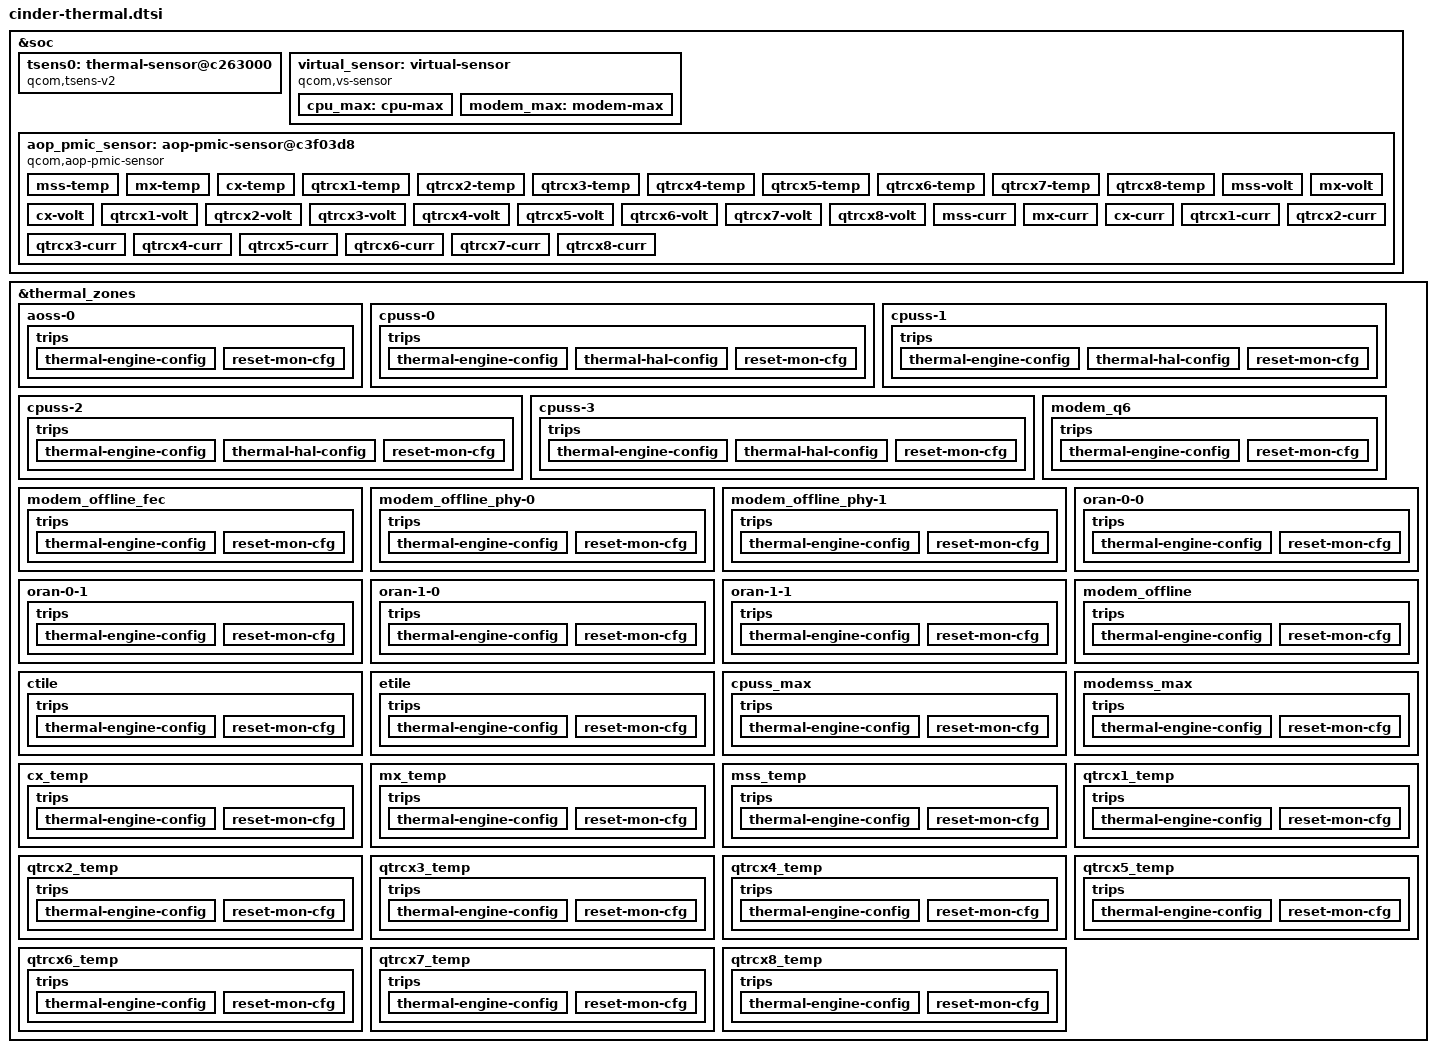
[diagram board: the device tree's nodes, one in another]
#include <dt-bindings/thermal/thermal_qti.h>

&soc {
	tsens0: thermal-sensor@c263000 {
		compatible = "qcom,tsens-v2";
		reg = <0x0c263000 0x1ff>, /* TM */
			<0x0c222000 0x1ff>; /* SROT */
		#qcom,sensors = <16>;
		interrupts = <GIC_SPI 499 IRQ_TYPE_LEVEL_HIGH>,
			     <GIC_SPI 501 IRQ_TYPE_LEVEL_HIGH>;
		interrupt-names = "uplow","critical";
		#thermal-sensor-cells = <1>;
	};

	virtual_sensor: virtual-sensor {
		compatible = "qcom,vs-sensor";
		#thermal-sensor-cells = <1>;

		cpu_max: cpu-max {
			sensor-names = "cpuss-0",
					"cpuss-1",
					"cpuss-2",
					"cpuss-3";
			qcom,logic = <1>;
		};

		modem_max: modem-max {
			sensor-names = "modem_q6",
					"modem_offline_fec",
					"modem_offline_phy-0",
					"modem_offline_phy-1",
					"modem_offline";
			qcom,logic = <1>;
		};
	};

    aop_pmic_sensor: aop-pmic-sensor@c3f03d8 {
        compatible = "qcom,aop-pmic-sensor";
		reg = <0x0c3e0200 0x140>;
		mboxes = <&qmp_aop 0>;
		#thermal-sensor-cells = <1>;

		mss-temp {
			qcom,pmic-id = <1>;
			qcom,type = <0>;
		};

		mx-temp {
			qcom,pmic-id = <2>;
			qcom,type = <0>;
		};

		cx-temp {
			qcom,pmic-id = <3>;
			qcom,type = <0>;
		};

		qtrcx1-temp {
			qcom,pmic-id = <13>;
			qcom,type = <0>;
		};

		qtrcx2-temp {
			qcom,pmic-id = <14>;
			qcom,type = <0>;
		};

		qtrcx3-temp {
			qcom,pmic-id = <15>;
			qcom,type = <0>;
		};

		qtrcx4-temp {
			qcom,pmic-id = <16>;
			qcom,type = <0>;
		};

		qtrcx5-temp {
			qcom,pmic-id = <17>;
			qcom,type = <0>;
		};

		qtrcx6-temp {
			qcom,pmic-id = <18>;
			qcom,type = <0>;
		};

		qtrcx7-temp {
			qcom,pmic-id = <19>;
			qcom,type = <0>;
		};

		qtrcx8-temp {
			qcom,pmic-id = <20>;
			qcom,type = <0>;
		};

		mss-volt {
			qcom,pmic-id = <1>;
			qcom,type = <1>;
		};

		mx-volt {
			qcom,pmic-id = <2>;
			qcom,type = <1>;
		};

		cx-volt {
			qcom,pmic-id = <3>;
			qcom,type = <1>;
		};

		qtrcx1-volt {
			qcom,pmic-id = <13>;
			qcom,type = <1>;
		};

		qtrcx2-volt {
			qcom,pmic-id = <14>;
			qcom,type = <1>;
		};

		qtrcx3-volt {
			qcom,pmic-id = <15>;
			qcom,type = <1>;
		};

		qtrcx4-volt {
			qcom,pmic-id = <16>;
			qcom,type = <1>;
		};

		qtrcx5-volt {
			qcom,pmic-id = <17>;
			qcom,type = <1>;
		};

		qtrcx6-volt {
			qcom,pmic-id = <18>;
			qcom,type = <1>;
		};

		qtrcx7-volt {
			qcom,pmic-id = <19>;
			qcom,type = <1>;
		};

		qtrcx8-volt {
			qcom,pmic-id = <20>;
			qcom,type = <1>;
		};

		mss-curr {
			qcom,pmic-id = <1>;
			qcom,type = <2>;
		};

		mx-curr {
			qcom,pmic-id = <2>;
			qcom,type = <2>;
		};

		cx-curr {
			qcom,pmic-id = <3>;
			qcom,type = <2>;
		};

		qtrcx1-curr {
			qcom,pmic-id = <13>;
			qcom,type = <2>;
		};

		qtrcx2-curr {
			qcom,pmic-id = <14>;
			qcom,type = <2>;
		};

		qtrcx3-curr {
			qcom,pmic-id = <15>;
			qcom,type = <2>;
		};

		qtrcx4-curr {
			qcom,pmic-id = <16>;
			qcom,type = <2>;
		};

		qtrcx5-curr {
			qcom,pmic-id = <17>;
			qcom,type = <2>;
		};

		qtrcx6-curr {
			qcom,pmic-id = <18>;
			qcom,type = <2>;
		};

		qtrcx7-curr {
			qcom,pmic-id = <19>;
			qcom,type = <2>;
		};

		qtrcx8-curr {
			qcom,pmic-id = <20>;
			qcom,type = <2>;
		};
    };
};

#include "cinder-thermal-modem.dtsi"

&thermal_zones {
	aoss-0 {
		polling-delay-passive = <0>;
		polling-delay = <0>;
		thermal-sensors = <&tsens0 0>;
		trips {
			thermal-engine-config {
				temperature = <125000>;
				hysteresis = <1000>;
				type = "passive";
			};

			reset-mon-cfg {
				temperature = <115000>;
				hysteresis = <5000>;
				type = "passive";
			};
		};
	};

	cpuss-0 {
		polling-delay-passive = <0>;
		polling-delay = <0>;
		thermal-sensors = <&tsens0 1>;
		trips {
			thermal-engine-config {
				temperature = <125000>;
				hysteresis = <1000>;
				type = "passive";
			};

			thermal-hal-config {
				temperature = <125000>;
				hysteresis = <1000>;
				type = "passive";
			};

			reset-mon-cfg {
				temperature = <115000>;
				hysteresis = <5000>;
				type = "passive";
			};
		};
	};

	cpuss-1 {
		polling-delay-passive = <0>;
		polling-delay = <0>;
		thermal-sensors = <&tsens0 2>;
		trips {
			thermal-engine-config {
				temperature = <125000>;
				hysteresis = <1000>;
				type = "passive";
			};

			thermal-hal-config {
				temperature = <125000>;
				hysteresis = <1000>;
				type = "passive";
			};

			reset-mon-cfg {
				temperature = <115000>;
				hysteresis = <5000>;
				type = "passive";
			};
		};
	};

	cpuss-2 {
		polling-delay-passive = <0>;
		polling-delay = <0>;
		thermal-sensors = <&tsens0 3>;
		trips {
			thermal-engine-config {
				temperature = <125000>;
				hysteresis = <1000>;
				type = "passive";
			};

			thermal-hal-config {
				temperature = <125000>;
				hysteresis = <1000>;
				type = "passive";
			};

			reset-mon-cfg {
				temperature = <115000>;
				hysteresis = <5000>;
				type = "passive";
			};
		};
	};

	cpuss-3 {
		polling-delay-passive = <0>;
		polling-delay = <0>;
		thermal-sensors = <&tsens0 4>;
		trips {
			thermal-engine-config {
				temperature = <125000>;
				hysteresis = <1000>;
				type = "passive";
			};

			thermal-hal-config {
				temperature = <125000>;
				hysteresis = <1000>;
				type = "passive";
			};

			reset-mon-cfg {
				temperature = <115000>;
				hysteresis = <5000>;
				type = "passive";
			};
		};
	};

	modem_q6 {
		polling-delay-passive = <0>;
		polling-delay = <0>;
		thermal-sensors = <&tsens0 5>;
		trips {
			thermal-engine-config {
				temperature = <125000>;
				hysteresis = <1000>;
				type = "passive";
			};

			reset-mon-cfg {
				temperature = <115000>;
				hysteresis = <5000>;
				type = "passive";
			};
		};
	};

	modem_offline_fec {
		polling-delay-passive = <0>;
		polling-delay = <0>;
		thermal-sensors = <&tsens0 6>;
		trips {
			thermal-engine-config {
				temperature = <125000>;
				hysteresis = <1000>;
				type = "passive";
			};

			reset-mon-cfg {
				temperature = <115000>;
				hysteresis = <5000>;
				type = "passive";
			};
		};
	};

	modem_offline_phy-0 {
		polling-delay-passive = <0>;
		polling-delay = <0>;
		thermal-sensors = <&tsens0 7>;
		trips {
			thermal-engine-config {
				temperature = <125000>;
				hysteresis = <1000>;
				type = "passive";
			};

			reset-mon-cfg {
				temperature = <115000>;
				hysteresis = <5000>;
				type = "passive";
			};
		};
	};

	modem_offline_phy-1 {
		polling-delay-passive = <0>;
		polling-delay = <0>;
		thermal-sensors = <&tsens0 8>;
		trips {
			thermal-engine-config {
				temperature = <125000>;
				hysteresis = <1000>;
				type = "passive";
			};

			reset-mon-cfg {
				temperature = <115000>;
				hysteresis = <5000>;
				type = "passive";
			};
		};
	};

	oran-0-0 {
		polling-delay-passive = <0>;
		polling-delay = <0>;
		thermal-sensors = <&tsens0 9>;
		trips {
			thermal-engine-config {
				temperature = <125000>;
				hysteresis = <1000>;
				type = "passive";
			};

			reset-mon-cfg {
				temperature = <115000>;
				hysteresis = <5000>;
				type = "passive";
			};
		};
	};

	oran-0-1 {
		polling-delay-passive = <0>;
		polling-delay = <0>;
		thermal-sensors = <&tsens0 10>;
		trips {
			thermal-engine-config {
				temperature = <125000>;
				hysteresis = <1000>;
				type = "passive";
			};

			reset-mon-cfg {
				temperature = <115000>;
				hysteresis = <5000>;
				type = "passive";
			};
		};
	};

	oran-1-0 {
		polling-delay-passive = <0>;
		polling-delay = <0>;
		thermal-sensors = <&tsens0 11>;
		trips {
			thermal-engine-config {
				temperature = <125000>;
				hysteresis = <1000>;
				type = "passive";
			};

			reset-mon-cfg {
				temperature = <115000>;
				hysteresis = <5000>;
				type = "passive";
			};
		};
	};

	oran-1-1 {
		polling-delay-passive = <0>;
		polling-delay = <0>;
		thermal-sensors = <&tsens0 12>;
		trips {
			thermal-engine-config {
				temperature = <125000>;
				hysteresis = <1000>;
				type = "passive";
			};

			reset-mon-cfg {
				temperature = <115000>;
				hysteresis = <5000>;
				type = "passive";
			};
		};
	};

	modem_offline {
		polling-delay-passive = <0>;
		polling-delay = <0>;
		thermal-sensors = <&tsens0 13>;
		trips {
			thermal-engine-config {
				temperature = <125000>;
				hysteresis = <1000>;
				type = "passive";
			};

			reset-mon-cfg {
				temperature = <115000>;
				hysteresis = <5000>;
				type = "passive";
			};
		};
	};

	ctile {
		polling-delay-passive = <0>;
		polling-delay = <0>;
		thermal-sensors = <&tsens0 14>;
		trips {
			thermal-engine-config {
				temperature = <125000>;
				hysteresis = <1000>;
				type = "passive";
			};

			reset-mon-cfg {
				temperature = <115000>;
				hysteresis = <5000>;
				type = "passive";
			};
		};
	};

	etile {
		polling-delay-passive = <0>;
		polling-delay = <0>;
		thermal-sensors = <&tsens0 15>;
		trips {
			thermal-engine-config {
				temperature = <125000>;
				hysteresis = <1000>;
				type = "passive";
			};

			reset-mon-cfg {
				temperature = <115000>;
				hysteresis = <5000>;
				type = "passive";
			};
		};
	};

	cpuss_max {
		polling-delay-passive = <0>;
		polling-delay = <0>;
		thermal-sensors = <&virtual_sensor 0>;
		trips {
			thermal-engine-config {
				temperature = <125000>;
				hysteresis = <1000>;
				type = "passive";
			};

			reset-mon-cfg {
				temperature = <115000>;
				hysteresis = <5000>;
				type = "passive";
			};
		};
	};

	modemss_max {
		polling-delay-passive = <0>;
		polling-delay = <0>;
		thermal-sensors = <&virtual_sensor 1>;
		trips {
			thermal-engine-config {
				temperature = <125000>;
				hysteresis = <1000>;
				type = "passive";
			};

			reset-mon-cfg {
				temperature = <115000>;
				hysteresis = <5000>;
				type = "passive";
			};
		};
	};

	cx_temp {
		polling-delay-passive = <0>;
		polling-delay = <0>;
		thermal-sensors = <&aop_pmic_sensor 1>;
		trips {
			thermal-engine-config {
				temperature = <125000>;
				hysteresis = <1000>;
				type = "passive";
			};

			reset-mon-cfg {
				temperature = <115000>;
				hysteresis = <5000>;
				type = "passive";
			};
		};
	};

	mx_temp {
		polling-delay-passive = <0>;
		polling-delay = <0>;
		thermal-sensors = <&aop_pmic_sensor 2>;
		trips {
			thermal-engine-config {
				temperature = <125000>;
				hysteresis = <1000>;
				type = "passive";
			};

			reset-mon-cfg {
				temperature = <115000>;
				hysteresis = <5000>;
				type = "passive";
			};
		};
	};

	mss_temp {
		polling-delay-passive = <0>;
		polling-delay = <0>;
		thermal-sensors = <&aop_pmic_sensor 3>;
		trips {
			thermal-engine-config {
				temperature = <125000>;
				hysteresis = <1000>;
				type = "passive";
			};

			reset-mon-cfg {
				temperature = <115000>;
				hysteresis = <5000>;
				type = "passive";
			};
		};
	};

	qtrcx1_temp {
		polling-delay-passive = <0>;
		polling-delay = <0>;
		thermal-sensors = <&aop_pmic_sensor 13>;
		trips {
			thermal-engine-config {
				temperature = <125000>;
				hysteresis = <1000>;
				type = "passive";
			};

			reset-mon-cfg {
				temperature = <115000>;
				hysteresis = <5000>;
				type = "passive";
			};
		};
	};

	qtrcx2_temp {
		polling-delay-passive = <0>;
		polling-delay = <0>;
		thermal-sensors = <&aop_pmic_sensor 14>;
		trips {
			thermal-engine-config {
				temperature = <125000>;
				hysteresis = <1000>;
				type = "passive";
			};

			reset-mon-cfg {
				temperature = <115000>;
				hysteresis = <5000>;
				type = "passive";
			};
		};
	};

	qtrcx3_temp {
		polling-delay-passive = <0>;
		polling-delay = <0>;
		thermal-sensors = <&aop_pmic_sensor 15>;
		trips {
			thermal-engine-config {
				temperature = <125000>;
				hysteresis = <1000>;
				type = "passive";
			};

			reset-mon-cfg {
				temperature = <115000>;
				hysteresis = <5000>;
				type = "passive";
			};
		};
	};

	qtrcx4_temp {
		polling-delay-passive = <0>;
		polling-delay = <0>;
		thermal-sensors = <&aop_pmic_sensor 16>;
		trips {
			thermal-engine-config {
				temperature = <125000>;
				hysteresis = <1000>;
				type = "passive";
			};

			reset-mon-cfg {
				temperature = <115000>;
				hysteresis = <5000>;
				type = "passive";
			};
		};
	};

	qtrcx5_temp {
		polling-delay-passive = <0>;
		polling-delay = <0>;
		thermal-sensors = <&aop_pmic_sensor 17>;
		trips {
			thermal-engine-config {
				temperature = <125000>;
				hysteresis = <1000>;
				type = "passive";
			};

			reset-mon-cfg {
				temperature = <115000>;
				hysteresis = <5000>;
				type = "passive";
			};
		};
	};

	qtrcx6_temp {
		polling-delay-passive = <0>;
		polling-delay = <0>;
		thermal-sensors = <&aop_pmic_sensor 18>;
		trips {
			thermal-engine-config {
				temperature = <125000>;
				hysteresis = <1000>;
				type = "passive";
			};

			reset-mon-cfg {
				temperature = <115000>;
				hysteresis = <5000>;
				type = "passive";
			};
		};
	};

	qtrcx7_temp {
		polling-delay-passive = <0>;
		polling-delay = <0>;
		thermal-sensors = <&aop_pmic_sensor 19>;
		trips {
			thermal-engine-config {
				temperature = <125000>;
				hysteresis = <1000>;
				type = "passive";
			};

			reset-mon-cfg {
				temperature = <115000>;
				hysteresis = <5000>;
				type = "passive";
			};
		};
	};

	qtrcx8_temp {
		polling-delay-passive = <0>;
		polling-delay = <0>;
		thermal-sensors = <&aop_pmic_sensor 20>;
		trips {
			thermal-engine-config {
				temperature = <125000>;
				hysteresis = <1000>;
				type = "passive";
			};

			reset-mon-cfg {
				temperature = <115000>;
				hysteresis = <5000>;
				type = "passive";
			};
		};
	};
};
